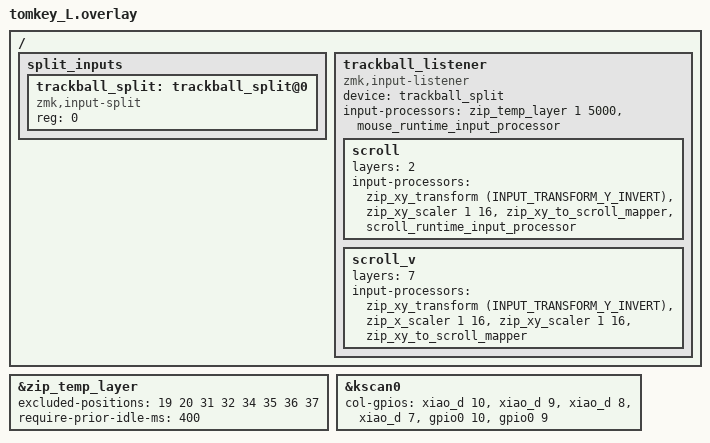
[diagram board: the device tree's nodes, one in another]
#include "tomkey.dtsi"
#include <dt-bindings/zmk/input_transform.h>
#include <input/processors.dtsi>
#include <input/processors/runtime-input-processor.dtsi>
#include <behaviors/battery_history_request.dtsi>
#include <zephyr/dt-bindings/input/input-event-codes.h>

/ {
    split_inputs {
        #address-cells = <1>;
        #size-cells = <0>;

        trackball_split: trackball_split@0 {
            compatible = "zmk,input-split";
            reg = <0>;
        };
    };

    trackball_listener: trackball_listener {
        compatible = "zmk,input-listener";
        status = "disabled";
        device = <&trackball_split>;
    };
};

&zip_temp_layer {
    /* マウスボタン(31:Comma, 32:Dot) と 修飾キー(34:Ctrl, 35:Alt, 36:Cmd, 37:Shift) のみAMLを維持 */
    /* K(19) L(20): K+L縦スクロールコンボ用に外してAMLを維持 */
    /* それ以外のキー（通常タイピングキーなど）を押すと、即座にAMLが解除される */
    excluded-positions = <19 20 31 32 34 35 36 37>;
    require-prior-idle-ms = <400>;
};

/* trackball_listener は Peripheral (R) 側 overlay で runtime-input-processor 方式として定義済み */
/* Central (L) 側では trackball_split 経由の受信のみ行う */
&trackball_listener {
    status = "okay";
    input-processors = <&zip_temp_layer 1 5000>, <&mouse_runtime_input_processor>;

    scroll {
        layers = <2>;
        input-processors = <&zip_xy_transform (INPUT_TRANSFORM_Y_INVERT)>, <&zip_xy_scaler 1 16>, <&zip_xy_to_scroll_mapper>, <&scroll_runtime_input_processor>;
    };

    scroll_v {
        /* layer 7 (縦スクロール専用): X軸を極小化し縦方向のみスクロール */
        layers = <7>;
        input-processors = <&zip_xy_transform (INPUT_TRANSFORM_Y_INVERT)>, <&zip_x_scaler 1 16>, <&zip_xy_scaler 1 16>, <&zip_xy_to_scroll_mapper>;
    };
};


&kscan0 {
        col-gpios
            = <&xiao_d 10 GPIO_ACTIVE_HIGH>
            , <&xiao_d 9 GPIO_ACTIVE_HIGH>
            , <&xiao_d 8 GPIO_ACTIVE_HIGH>
            , <&xiao_d 7 GPIO_ACTIVE_HIGH>
            , <&gpio0 10 GPIO_ACTIVE_HIGH>
            , <&gpio0 9 GPIO_ACTIVE_HIGH>
            ;
};
